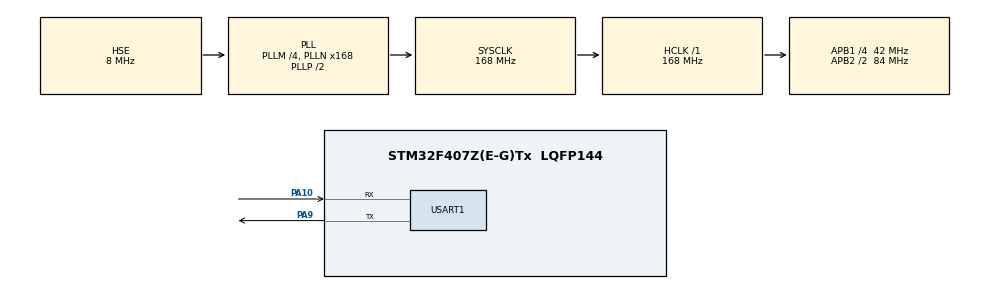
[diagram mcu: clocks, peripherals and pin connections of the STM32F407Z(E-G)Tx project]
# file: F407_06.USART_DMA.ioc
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Mcu.Family=STM32F4
RCC.PLLSourceVirtual=RCC_PLLSOURCE_HSE
PH0-OSC_IN.Signal=RCC_OSC_IN
RCC.CortexFreq_Value=168000000
Dma.USART1_RX.0.PeriphDataAlignment=DMA_PDATAALIGN_BYTE
PA10.Mode=Asynchronous
RCC.APB1CLKDivider=RCC_HCLK_DIV4
RCC.SYSCLKSource=RCC_SYSCLKSOURCE_PLLCLK
ProjectManager.StackSize=0x400
PA13.Signal=SYS_JTMS-SWDIO
PA9.Mode=Asynchronous
ProjectManager.TargetToolchain=STM32CubeIDE
RCC.HCLKFreq_Value=168000000
Dma.USART1_RX.0.Direction=DMA_PERIPH_TO_MEMORY
RCC.APB2TimFreq_Value=168000000
PA9.Signal=USART1_TX
RCC.LSE_VALUE=32768
RCC.AHBFreq_Value=168000000
PH0-OSC_IN.Mode=HSE-External-Oscillator
Dma.USART1_RX.0.PeriphInc=DMA_PINC_DISABLE
Dma.USART1_RX.0.Priority=DMA_PRIORITY_LOW
RCC.HSE_VALUE=8000000
board=custom
RCC.VCOOutputFreq_Value=336000000
RCC.APB2Freq_Value=84000000
PA14.Mode=Serial_Wire
PH1-OSC_OUT.Signal=RCC_OSC_OUT
Dma.USART1_RX.0.MemDataAlignment=DMA_MDATAALIGN_BYTE
Dma.USART1_RX.0.MemInc=DMA_MINC_ENABLE
PA13.Mode=Serial_Wire
Mcu.Name=STM32F407Z(E-G)Tx
PH1-OSC_OUT.Mode=HSE-External-Oscillator
RCC.48MHZClocksFreq_Value=84000000
RCC.SYSCLKFreq_VALUE=168000000
Mcu.Package=LQFP144
USART1.VirtualMode=VM_ASYNC
PA10.Signal=USART1_RX
PA14.Signal=SYS_JTCK-SWCLK
ProjectManager.HeapSize=0x200
RCC.HSI_VALUE=16000000
NVIC.PriorityGroup=NVIC_PRIORITYGROUP_4
Dma.USART1_RX.0.FIFOMode=DMA_FIFOMODE_DISABLE
RCC.APB2CLKDivider=RCC_HCLK_DIV2
NVIC.DMA2_Stream2_IRQn=true\:0\:0\:false\:false\:true\:false\:true
RCC.PLLM=4
RCC.PLLN=168
RCC.APB1TimFreq_Value=84000000
Dma.USART1_RX.0.Mode=DMA_CIRCULAR
NVIC.USART1_IRQn=true\:0\:0\:false\:false\:true\:true\:true
RCC.APB1Freq_Value=42000000
Dma.Request0=USART1_RX
Dma.USART1_RX.0.Instance=DMA2_Stream2

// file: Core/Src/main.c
/* USER CODE BEGIN Header */
/**
 ******************************************************************************
 * @file           : main.c
 * @brief          : Main program body
 ******************************************************************************
 * @attention
 *
 * <h2><center>&copy; Copyright (c) 2021 STMicroelectronics.
 * All rights reserved.</center></h2>
 *
 * This software component is licensed by ST under BSD 3-Clause license,
 * the "License"; You may not use this file except in compliance with the
 * License. You may obtain a copy of the License at:
 *                        opensource.org/licenses/BSD-3-Clause
 *
 ******************************************************************************
 */
/* USER CODE END Header */
#include "main.h"
#include "dma.h"
#include "usart.h"
#include "gpio.h"

void SystemClock_Config(void);

/* USER CODE BEGIN 0 */
uint8_t receive_buff[32] = {0};
uint16_t coordinate_XY[32][2] = {0};
uint8_t i = 0;

/* USER CODE END 0 */

int main(void)
{

  /* MCU Configuration--------------------------------------------------------*/

  /* Reset of all peripherals, Initializes the Flash interface and the Systick. */
  HAL_Init();

  /* Configure the system clock */
  SystemClock_Config();

  /* Initialize all configured peripherals */
  MX_GPIO_Init();
  MX_DMA_Init();
  MX_USART1_UART_Init();

  /* Infinite loop */
  /* USER CODE BEGIN WHILE */
	while (1) {
//		printf("coordinate_XY[0] = %d\r\n", coordinate_XY[0][0]);
//		printf("coordinate_XY[1] = %d\r\n", coordinate_XY[1][0]);
//		printf("coordinate_XY[2] = %d\r\n", coordinate_XY[2][0]);
//		printf("coordinate_XY[3] = %d\r\n", coordinate_XY[3][0]);
    /* USER CODE END WHILE */

	}
}

void SystemClock_Config(void)
{
  RCC_OscInitTypeDef RCC_OscInitStruct = {0};
  RCC_ClkInitTypeDef RCC_ClkInitStruct = {0};

  /** Configure the main internal regulator output voltage
  */
  __HAL_RCC_PWR_CLK_ENABLE();
  __HAL_PWR_VOLTAGESCALING_CONFIG(PWR_REGULATOR_VOLTAGE_SCALE1);
  /** Initializes the RCC Oscillators according to the specified parameters
  * in the RCC_OscInitTypeDef structure.
  */
  RCC_OscInitStruct.OscillatorType = RCC_OSCILLATORTYPE_HSE;
  RCC_OscInitStruct.HSEState = RCC_HSE_ON;
  RCC_OscInitStruct.PLL.PLLState = RCC_PLL_ON;
  RCC_OscInitStruct.PLL.PLLSource = RCC_PLLSOURCE_HSE;
  RCC_OscInitStruct.PLL.PLLM = 4;
  RCC_OscInitStruct.PLL.PLLN = 168;
  RCC_OscInitStruct.PLL.PLLP = RCC_PLLP_DIV2;
  RCC_OscInitStruct.PLL.PLLQ = 4;
  if (HAL_RCC_OscConfig(&RCC_OscInitStruct) != HAL_OK)
  {
    Error_Handler();
  }
  /** Initializes the CPU, AHB and APB buses clocks
  */
  RCC_ClkInitStruct.ClockType = RCC_CLOCKTYPE_HCLK|RCC_CLOCKTYPE_SYSCLK
                              |RCC_CLOCKTYPE_PCLK1|RCC_CLOCKTYPE_PCLK2;
  RCC_ClkInitStruct.SYSCLKSource = RCC_SYSCLKSOURCE_PLLCLK;
  RCC_ClkInitStruct.AHBCLKDivider = RCC_SYSCLK_DIV1;
  RCC_ClkInitStruct.APB1CLKDivider = RCC_HCLK_DIV4;
  RCC_ClkInitStruct.APB2CLKDivider = RCC_HCLK_DIV2;

  if (HAL_RCC_ClockConfig(&RCC_ClkInitStruct, FLASH_LATENCY_5) != HAL_OK)
  {
    Error_Handler();
  }
}

/* USER CODE BEGIN 4 */
// 须在头文件中添加 #include <stdio.h>
//////////////////////////////////////////////////////////////////
// 加入以下代码,支持printf函数,而不需要选择use MicroLIB
// MDK中同样定义了 __GNUC__，使用__ARMCC_VERSION 或  __CC_ARM 区分MDK和STM32CubeIDE
// MDK预定义宏，详见 ：https://www.keil.com/support/man/docs/armcc/armcc_chr1359125007083.htm
#ifdef __CC_ARM // 或 #ifdef __ARMCC_VERSION
  #define PUTCHAR_PROTOTYPE int fputc(int ch, FILE *f)
#else
#define PUTCHAR_PROTOTYPE int __io_putchar(int ch)
#endif
#if 1

FILE __stdout;
//定义_sys_exit()以避免使用半主机模式
void _sys_exit(int x) {
	x = x;
}
//重定义fputc函数
PUTCHAR_PROTOTYPE {
	// 具体哪个串口可以更改huart2为其它串口
	// HAL_UART_Transmit(&huart2, (uint8_t *)&ch, 1 , 0xffff);
	while ((USART1->SR & 0X40) == 0) {
	}; //循环发送,直到发送完毕
	USART1->DR = (uint8_t) ch;

//  while ((USART2->SR & 0X40) == 0) {
//  }; //循环发送,直到发送完毕
//  USART2->DR = (uint8_t) ch;

	return ch;
}
#endif

/* USER CODE END 4 */

void Error_Handler(void)
{
	__disable_irq();
	while (1) {
	}
}

/************************ (C) COPYRIGHT STMicroelectronics *****END OF FILE****/
